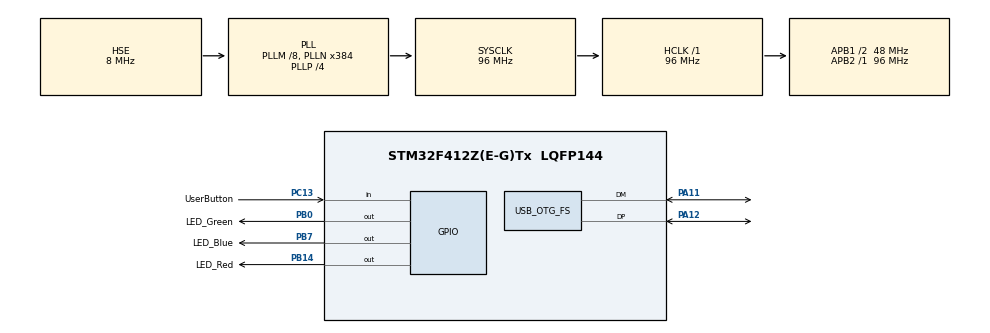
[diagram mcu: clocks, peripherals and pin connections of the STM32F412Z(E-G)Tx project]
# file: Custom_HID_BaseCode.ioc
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Mcu.Family=STM32F4
Mcu.Name=STM32F412Z(E-G)Tx
Mcu.Package=LQFP144
NVIC.OTG_FS_IRQn=true\:0\:0\:false\:false\:true\:false\:true\:true
NVIC.PriorityGroup=NVIC_PRIORITYGROUP_4
PA11.Mode=Device_Only
PA11.Signal=USB_OTG_FS_DM
PA12.Mode=Device_Only
PA12.Signal=USB_OTG_FS_DP
PB0.GPIO_Label=LED_Green
PB0.Signal=GPIO_Output
PB14.GPIO_Label=LED_Red
PB14.Signal=GPIO_Output
PB7.GPIO_Label=LED_Blue
PB7.Signal=GPIO_Output
PC13.GPIO_Label=UserButton
PC13.Signal=GPIO_Input
PH0\ -\ OSC_IN.Mode=HSE-External-Clock-Source
PH0\ -\ OSC_IN.Signal=RCC_OSC_IN
PH1\ -\ OSC_OUT.Mode=HSE-External-Clock-Source
PH1\ -\ OSC_OUT.Signal=RCC_OSC_OUT
ProjectManager.HeapSize=0x200
ProjectManager.StackSize=0x400
ProjectManager.TargetToolchain=Makefile
RCC.48MHZClocksFreq_Value=24000000
RCC.AHBFreq_Value=96000000
RCC.APB1CLKDivider=RCC_HCLK_DIV2
RCC.APB1Freq_Value=48000000
RCC.APB1TimFreq_Value=96000000
RCC.APB2Freq_Value=96000000
RCC.APB2TimFreq_Value=96000000
RCC.CortexFreq_Value=96000000
RCC.HCLKFreq_Value=96000000
RCC.HSE_VALUE=8000000
RCC.HSI_VALUE=16000000
RCC.PLLM=8
RCC.PLLMUL=RCC_PLL_MUL9
RCC.PLLN=384
RCC.PLLP=RCC_PLLP_DIV4
RCC.PLLQ=8
RCC.PLLSourceVirtual=RCC_PLLSOURCE_HSE
RCC.PRESCALERUSB=RCC_USBCLKSOURCE_PLL_DIV1_5
RCC.SYSCLKFreq_VALUE=96000000
RCC.SYSCLKSource=RCC_SYSCLKSOURCE_PLLCLK
RCC.SYSCLKSourceVirtual=RCC_SYSCLKSOURCE_PLLCLK
RCC.USBFreq_Value=48000000
RCC.VCOOutputFreq_Value=384000000
USB_DEVICE.CLASS_NAME_FS=CUSTOM_HID
USB_DEVICE.PRODUCT_STRING_CUSTOMHID_FS=BALLUFF USB Device
USB_DEVICE.VirtualMode=CustomHid
USB_DEVICE.VirtualModeFS=Custom_Hid_FS
USB_OTG_FS.VirtualMode=Device_Only
VP_USB_DEVICE_VS_USB_DEVICE_CUSTOM_HID_FS.Mode=CUSTOM_HID_FS
board=NUCLEO-F412ZG

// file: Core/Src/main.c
/* USER CODE BEGIN Header */
/**
 ******************************************************************************
 * @file           : main.c
 * @brief          : Main program body
 ******************************************************************************
 * @attention
 *
 * Copyright (c) 2023 STMicroelectronics.
 * All rights reserved.
 *
 * This software is licensed under terms that can be found in the LICENSE file
 * in the root directory of this software component.
 * If no LICENSE file comes with this software, it is provided AS-IS.
 *
 ******************************************************************************
 */
/* USER CODE END Header */
#include "main.h"
#include "usb_device.h"
/* USER CODE BEGIN Includes */
#include "../../dataprovider.h"
#include "../../rust_wrapper.h"
#include "../../Middlewares/ST/STM32_USB_Device_Library/Class/CustomHID/Inc/usbd_customhid.h"
#include "../../USB_DEVICE/App/usbd_custom_hid_if.h"
/* USER CODE END Includes */

/* USER CODE BEGIN PV */
uint8_t bufferForButton[0x40];
uint8_t button_val;
uint8_t button_available_to_report = 1;
extern USBD_HandleTypeDef hUsbDeviceFS;
/* USER CODE END PV */

void SystemClock_Config(void);
static void MX_GPIO_Init(void);

int main(void)
{
  /* USER CODE BEGIN 1 */
  initDataprovider();

  /* USER CODE END 1 */

  /* MCU Configuration--------------------------------------------------------*/

  /* Reset of all peripherals, Initializes the Flash interface and the Systick. */
  HAL_Init();

  /* Configure the system clock */
  SystemClock_Config();

  /* Initialize all configured peripherals */
  MX_GPIO_Init();
  MX_USB_DEVICE_Init();

  /* Infinite loop */
  while (1)
  {
    HAL_Delay(getLED_Green_speed());
    HAL_GPIO_TogglePin(LED_Green_GPIO_Port, LED_Green_Pin);

    if (getLDs() == 2 && ((int)getLED_Blue_isActive() != (int)getLED_Blue_currentState()))
    {
      HAL_GPIO_TogglePin(LED_Blue_GPIO_Port, LED_Blue_Pin);
      setLED_Blue_currentState((int)getLED_Blue_isActive());
    }
    else if (getLDs() == 3 && ((int)getLED_Red_isActive() != (int)getLED_Red_currentState()))
    {
      HAL_GPIO_TogglePin(LED_Red_GPIO_Port, LED_Red_Pin);
      setLED_Red_currentState((int)getLED_Red_isActive());
    }

    button_val = HAL_GPIO_ReadPin(UserButton_GPIO_Port, UserButton_Pin);

    if (button_val == 1 && button_available_to_report == 1)
    {
      button_available_to_report = 0;
      memset(bufferForButton, 0, 0x40);
      bufferForButton[1] = 66; // B
      bufferForButton[2] = 68; // D aka Button Down
      USBD_CUSTOM_HID_SendReport(&hUsbDeviceFS, bufferForButton, 0x40);
    }
    else if (button_val == 0 && button_available_to_report == 0)
    {
      memset(bufferForButton, 0, 0x40);
      bufferForButton[1] = 66; // B
      bufferForButton[2] = 85; // U aka Button Up
      USBD_CUSTOM_HID_SendReport(&hUsbDeviceFS, bufferForButton, 0x40);
      button_available_to_report = 1;
    }

  }
}

void SystemClock_Config(void)
{
  RCC_OscInitTypeDef RCC_OscInitStruct = {0};
  RCC_ClkInitTypeDef RCC_ClkInitStruct = {0};

  /** Configure the main internal regulator output voltage
   */
  __HAL_RCC_PWR_CLK_ENABLE();
  __HAL_PWR_VOLTAGESCALING_CONFIG(PWR_REGULATOR_VOLTAGE_SCALE1);

  /** Initializes the RCC Oscillators according to the specified parameters
   * in the RCC_OscInitTypeDef structure.
   */
  RCC_OscInitStruct.OscillatorType = RCC_OSCILLATORTYPE_HSE;
  RCC_OscInitStruct.HSEState = RCC_HSE_BYPASS;
  RCC_OscInitStruct.PLL.PLLState = RCC_PLL_ON;
  RCC_OscInitStruct.PLL.PLLSource = RCC_PLLSOURCE_HSE;
  RCC_OscInitStruct.PLL.PLLM = 8;
  RCC_OscInitStruct.PLL.PLLN = 384;
  RCC_OscInitStruct.PLL.PLLP = RCC_PLLP_DIV4;
  RCC_OscInitStruct.PLL.PLLQ = 8;
  RCC_OscInitStruct.PLL.PLLR = 2;
  if (HAL_RCC_OscConfig(&RCC_OscInitStruct) != HAL_OK)
  {
    Error_Handler();
  }

  /** Initializes the CPU, AHB and APB buses clocks
   */
  RCC_ClkInitStruct.ClockType = RCC_CLOCKTYPE_HCLK | RCC_CLOCKTYPE_SYSCLK | RCC_CLOCKTYPE_PCLK1 | RCC_CLOCKTYPE_PCLK2;
  RCC_ClkInitStruct.SYSCLKSource = RCC_SYSCLKSOURCE_PLLCLK;
  RCC_ClkInitStruct.AHBCLKDivider = RCC_SYSCLK_DIV1;
  RCC_ClkInitStruct.APB1CLKDivider = RCC_HCLK_DIV2;
  RCC_ClkInitStruct.APB2CLKDivider = RCC_HCLK_DIV1;

  if (HAL_RCC_ClockConfig(&RCC_ClkInitStruct, FLASH_LATENCY_3) != HAL_OK)
  {
    Error_Handler();
  }
}

static void MX_GPIO_Init(void)
{
  GPIO_InitTypeDef GPIO_InitStruct = {0};

  /* GPIO Ports Clock Enable */
  __HAL_RCC_GPIOC_CLK_ENABLE();
  __HAL_RCC_GPIOH_CLK_ENABLE();
  __HAL_RCC_GPIOB_CLK_ENABLE();
  __HAL_RCC_GPIOA_CLK_ENABLE();

  /*Configure GPIO pin Output Level */
  HAL_GPIO_WritePin(GPIOB, LED_Green_Pin | LED_Red_Pin | LED_Blue_Pin, GPIO_PIN_RESET);

  /*Configure GPIO pin : UserButton_Pin */
  GPIO_InitStruct.Pin = UserButton_Pin;
  GPIO_InitStruct.Mode = GPIO_MODE_INPUT;
  GPIO_InitStruct.Pull = GPIO_NOPULL;
  HAL_GPIO_Init(UserButton_GPIO_Port, &GPIO_InitStruct);

  /*Configure GPIO pins : LED_Green_Pin LED_Red_Pin LED_Blue_Pin */
  GPIO_InitStruct.Pin = LED_Green_Pin | LED_Red_Pin | LED_Blue_Pin;
  GPIO_InitStruct.Mode = GPIO_MODE_OUTPUT_PP;
  GPIO_InitStruct.Pull = GPIO_NOPULL;
  GPIO_InitStruct.Speed = GPIO_SPEED_FREQ_LOW;
  HAL_GPIO_Init(GPIOB, &GPIO_InitStruct);

}

void Error_Handler(void)
{
  __disable_irq();
  while (1)
  {
  }
}
